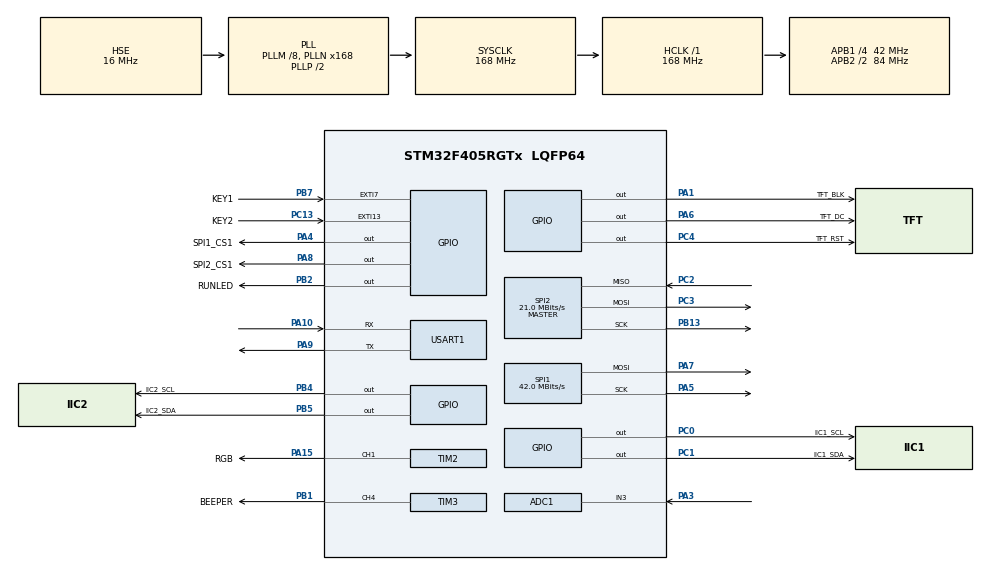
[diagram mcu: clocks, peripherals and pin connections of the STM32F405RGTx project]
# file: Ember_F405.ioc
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ADC1.Channel-0\#ChannelRegularConversion=ADC_CHANNEL_3
ADC1.NbrOfConversionFlag=1
ADC1.Rank-0\#ChannelRegularConversion=1
ADC1.SamplingTime-0\#ChannelRegularConversion=ADC_SAMPLETIME_3CYCLES
ADC1.master=1
Dma.Request0=SPI1_TX
Dma.Request1=TIM2_CH1
Dma.SPI1_TX.0.Direction=DMA_MEMORY_TO_PERIPH
Dma.SPI1_TX.0.FIFOMode=DMA_FIFOMODE_DISABLE
Dma.SPI1_TX.0.Instance=DMA2_Stream3
Dma.SPI1_TX.0.MemDataAlignment=DMA_MDATAALIGN_BYTE
Dma.SPI1_TX.0.MemInc=DMA_MINC_ENABLE
Dma.SPI1_TX.0.Mode=DMA_NORMAL
Dma.SPI1_TX.0.PeriphDataAlignment=DMA_PDATAALIGN_BYTE
Dma.SPI1_TX.0.PeriphInc=DMA_PINC_DISABLE
Dma.SPI1_TX.0.Priority=DMA_PRIORITY_HIGH
Dma.TIM2_CH1.1.Direction=DMA_MEMORY_TO_PERIPH
Dma.TIM2_CH1.1.FIFOMode=DMA_FIFOMODE_DISABLE
Dma.TIM2_CH1.1.Instance=DMA1_Stream5
Dma.TIM2_CH1.1.MemDataAlignment=DMA_MDATAALIGN_WORD
Dma.TIM2_CH1.1.MemInc=DMA_MINC_ENABLE
Dma.TIM2_CH1.1.Mode=DMA_NORMAL
Dma.TIM2_CH1.1.PeriphDataAlignment=DMA_PDATAALIGN_WORD
Dma.TIM2_CH1.1.PeriphInc=DMA_PINC_DISABLE
Dma.TIM2_CH1.1.Priority=DMA_PRIORITY_VERY_HIGH
Mcu.Family=STM32F4
Mcu.Name=STM32F405RGTx
Mcu.Package=LQFP64
NVIC.DMA1_Stream5_IRQn=true\:0\:0\:false\:false\:true\:false\:true\:true
NVIC.DMA2_Stream3_IRQn=true\:0\:0\:false\:false\:true\:false\:true\:true
NVIC.EXTI15_10_IRQn=true\:4\:0\:true\:false\:true\:true\:true\:true
NVIC.EXTI9_5_IRQn=true\:4\:0\:true\:false\:true\:true\:true\:true
NVIC.PriorityGroup=NVIC_PRIORITYGROUP_4
NVIC.SPI1_IRQn=true\:5\:0\:true\:false\:true\:true\:true\:true
NVIC.TIM1_TRG_COM_TIM11_IRQn=true\:15\:0\:false\:false\:true\:false\:true\:true
NVIC.TIM1_UP_TIM10_IRQn=true\:0\:0\:false\:false\:true\:true\:true\:true
NVIC.TimeBase=TIM1_TRG_COM_TIM11_IRQn
NVIC.TimeBaseIP=TIM11
PA1.GPIO_Label=TFT_BLK
PA1.Signal=GPIO_Output
PA10.Mode=Asynchronous
PA10.Signal=USART1_RX
PA13.Mode=Serial_Wire
PA13.Signal=SYS_JTMS-SWDIO
PA14.Mode=Serial_Wire
PA14.Signal=SYS_JTCK-SWCLK
PA15.GPIO_Label=RGB
PA15.GPIO_Speed=GPIO_SPEED_FREQ_VERY_HIGH
PA15.Signal=S_TIM2_CH1_ETR
PA3.Signal=ADCx_IN3
PA4.GPIO_Label=SPI1_CS1
PA4.Signal=GPIO_Output
PA5.GPIO_PuPd=GPIO_NOPULL
PA5.Mode=TX_Only_Simplex_Unidirect_Master
PA5.Signal=SPI1_SCK
PA6.GPIO_Label=TFT_DC
PA6.Signal=GPIO_Output
PA7.GPIO_PuPd=GPIO_NOPULL
PA7.Mode=TX_Only_Simplex_Unidirect_Master
PA7.Signal=SPI1_MOSI
PA8.GPIO_Label=SPI2_CS1
PA8.Signal=GPIO_Output
PA9.Mode=Asynchronous
PA9.Signal=USART1_TX
PB1.GPIO_Label=BEEPER
PB1.GPIO_Speed=GPIO_SPEED_FREQ_VERY_HIGH
PB1.Signal=S_TIM3_CH4
PB13.Mode=Full_Duplex_Master
PB13.Signal=SPI2_SCK
PB2.GPIO_Label=RUNLED
PB2.Signal=GPIO_Output
PB4.GPIO_Label=IIC2_SCL
PB4.Signal=GPIO_Output
PB5.GPIO_Label=IIC2_SDA
PB5.Signal=GPIO_Output
PB7.GPIO_Label=KEY1
PB7.GPIO_ModeDefaultEXTI=GPIO_MODE_IT_RISING_FALLING
PB7.GPIO_PuPd=GPIO_PULLUP
PB7.Signal=GPXTI7
PC0.GPIO_Label=IIC1_SCL
PC0.Signal=GPIO_Output
PC1.GPIO_Label=IIC1_SDA
PC1.Signal=GPIO_Output
PC13-ANTI_TAMP.GPIO_Label=KEY2
PC13-ANTI_TAMP.GPIO_ModeDefaultEXTI=GPIO_MODE_IT_RISING_FALLING
PC13-ANTI_TAMP.GPIO_PuPd=GPIO_PULLUP
PC13-ANTI_TAMP.Signal=GPXTI13
PC2.Mode=Full_Duplex_Master
PC2.Signal=SPI2_MISO
PC3.Mode=Full_Duplex_Master
PC3.Signal=SPI2_MOSI
PC4.GPIO_Label=TFT_RST
PC4.Signal=GPIO_Output
PH0-OSC_IN.Mode=HSE-External-Oscillator
PH0-OSC_IN.Signal=RCC_OSC_IN
PH1-OSC_OUT.Mode=HSE-External-Oscillator
PH1-OSC_OUT.Signal=RCC_OSC_OUT
ProjectManager.HeapSize=0x200
ProjectManager.StackSize=0x800
ProjectManager.TargetToolchain=MDK-ARM V5.32
RCC.48MHZClocksFreq_Value=48000000
RCC.AHBFreq_Value=168000000
RCC.APB1CLKDivider=RCC_HCLK_DIV4
RCC.APB1Freq_Value=42000000
RCC.APB1TimFreq_Value=84000000
RCC.APB2CLKDivider=RCC_HCLK_DIV2
RCC.APB2Freq_Value=84000000
RCC.APB2TimFreq_Value=168000000
RCC.CortexFreq_Value=168000000
RCC.HCLKFreq_Value=168000000
RCC.HSE_VALUE=16000000
RCC.HSI_VALUE=16000000
RCC.LSE_VALUE=32768
RCC.PLLM=8
RCC.PLLN=168
RCC.PLLQ=7
RCC.PLLSourceVirtual=RCC_PLLSOURCE_HSE
RCC.SYSCLKFreq_VALUE=168000000
RCC.SYSCLKSource=RCC_SYSCLKSOURCE_PLLCLK
RCC.VCOOutputFreq_Value=336000000
SH.ADCx_IN3.0=ADC1_IN3,IN3
SH.S_TIM2_CH1_ETR.0=TIM2_CH1,PWM Generation1 CH1
SH.S_TIM3_CH4.0=TIM3_CH4,PWM Generation4 CH4
SPI1.BaudRatePrescaler=SPI_BAUDRATEPRESCALER_2
SPI1.CLKPhase=SPI_PHASE_2EDGE
SPI1.CLKPolarity=SPI_POLARITY_HIGH
SPI1.CalculateBaudRate=42.0 MBits/s
SPI1.Direction=SPI_DIRECTION_2LINES
SPI1.Mode=SPI_MODE_MASTER
SPI1.VirtualType=VM_MASTER
SPI2.BaudRatePrescaler=SPI_BAUDRATEPRESCALER_2
SPI2.CalculateBaudRate=21.0 MBits/s
SPI2.Direction=SPI_DIRECTION_2LINES
SPI2.Mode=SPI_MODE_MASTER
SPI2.VirtualType=VM_MASTER
TIM10.Period=999
TIM10.Prescaler=999
TIM2.Channel-PWM\ Generation1\ CH1=TIM_CHANNEL_1
TIM2.OCFastMode_PWM-PWM\ Generation1\ CH1=TIM_OCFAST_DISABLE
TIM2.Period=105-1
TIM3.Channel-PWM\ Generation4\ CH4=TIM_CHANNEL_4
TIM3.Period=1000-1
TIM3.Prescaler=84-1
USART1.VirtualMode=VM_ASYNC
VP_SYS_VS_tim11.Mode=TIM11
VP_TIM10_VS_ClockSourceINT.Mode=Enable_Timer
board=custom

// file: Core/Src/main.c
/* USER CODE BEGIN Header */
/**
  ******************************************************************************
  * @file           : main.c
  * @brief          : Main program body
  ******************************************************************************
  * @attention
  *
  * Copyright (c) 2024 STMicroelectronics.
  * All rights reserved.
  *
  * This software is licensed under terms that can be found in the LICENSE file
  * in the root directory of this software component.
  * If no LICENSE file comes with this software, it is provided AS-IS.
  *
  ******************************************************************************
  */
/* USER CODE END Header */
#include "main.h"
#include "adc.h"
#include "dma.h"
#include "spi.h"
#include "tim.h"
#include "usart.h"
#include "gpio.h"

/* USER CODE BEGIN Includes */
#include "FreeRTOS_main.h"

/*LVGL*********************************************************************************************/
#include "lvgl.h"
#include "lv_port_disp_template.h"
#include "../generated/gui_guider.h"
#include "../generated/events_init.h"
#include "lv_demo_benchmark.h"
/******************************************************************************************************/

/* USER CODE END Includes */

void SystemClock_Config(void);

int main(void)
{

  /* MCU Configuration--------------------------------------------------------*/

  /* Reset of all peripherals, Initializes the Flash interface and the Systick. */
   HAL_Init();

  /* Configure the system clock */
  SystemClock_Config();

  /* USER CODE BEGIN SysInit */

//  Key_Init(&key1, KEY1_GPIO_Port, KEY1_Pin,"KEY1"); //按键实例初始化
//  Key_Init(&key2, KEY2_GPIO_Port, KEY2_Pin,"KEY2"); //按键实例初始化
  /* USER CODE END SysInit */

  /* Initialize all configured peripherals */
  MX_GPIO_Init();
  MX_DMA_Init();
  MX_SPI1_Init();
  MX_SPI2_Init();
  MX_TIM3_Init();
  MX_TIM10_Init();
  MX_ADC1_Init();
  MX_USART1_UART_Init();
  MX_TIM2_Init();
  /* USER CODE BEGIN 2 */

  /*LVGL 界面初始化*/
	lv_init();											//lvgl系统初始化
  lv_port_disp_init();						//lvgl显示接口初始化,放在lv_init()的后面

	freertos_start();//开启任务调度

  /* USER CODE END 2 */

  /* Infinite loop */
  while (1)
  {

  }
}

void SystemClock_Config(void)
{
  RCC_OscInitTypeDef RCC_OscInitStruct = {0};
  RCC_ClkInitTypeDef RCC_ClkInitStruct = {0};

  /** Configure the main internal regulator output voltage
  */
  __HAL_RCC_PWR_CLK_ENABLE();
  __HAL_PWR_VOLTAGESCALING_CONFIG(PWR_REGULATOR_VOLTAGE_SCALE1);

  /** Initializes the RCC Oscillators according to the specified parameters
  * in the RCC_OscInitTypeDef structure.
  */
  RCC_OscInitStruct.OscillatorType = RCC_OSCILLATORTYPE_HSE;
  RCC_OscInitStruct.HSEState = RCC_HSE_ON;
  RCC_OscInitStruct.PLL.PLLState = RCC_PLL_ON;
  RCC_OscInitStruct.PLL.PLLSource = RCC_PLLSOURCE_HSE;
  RCC_OscInitStruct.PLL.PLLM = 8;
  RCC_OscInitStruct.PLL.PLLN = 168;
  RCC_OscInitStruct.PLL.PLLP = RCC_PLLP_DIV2;
  RCC_OscInitStruct.PLL.PLLQ = 7;
  if (HAL_RCC_OscConfig(&RCC_OscInitStruct) != HAL_OK)
  {
    Error_Handler();
  }

  /** Initializes the CPU, AHB and APB buses clocks
  */
  RCC_ClkInitStruct.ClockType = RCC_CLOCKTYPE_HCLK|RCC_CLOCKTYPE_SYSCLK
                              |RCC_CLOCKTYPE_PCLK1|RCC_CLOCKTYPE_PCLK2;
  RCC_ClkInitStruct.SYSCLKSource = RCC_SYSCLKSOURCE_PLLCLK;
  RCC_ClkInitStruct.AHBCLKDivider = RCC_SYSCLK_DIV1;
  RCC_ClkInitStruct.APB1CLKDivider = RCC_HCLK_DIV4;
  RCC_ClkInitStruct.APB2CLKDivider = RCC_HCLK_DIV2;

  if (HAL_RCC_ClockConfig(&RCC_ClkInitStruct, FLASH_LATENCY_5) != HAL_OK)
  {
    Error_Handler();
  }
}

void HAL_TIM_PeriodElapsedCallback(TIM_HandleTypeDef *htim)
{
  if (htim->Instance == TIM11) {
    HAL_IncTick();
  }
}

void Error_Handler(void)
{
  __disable_irq();
  while (1)
  {
  }
}
